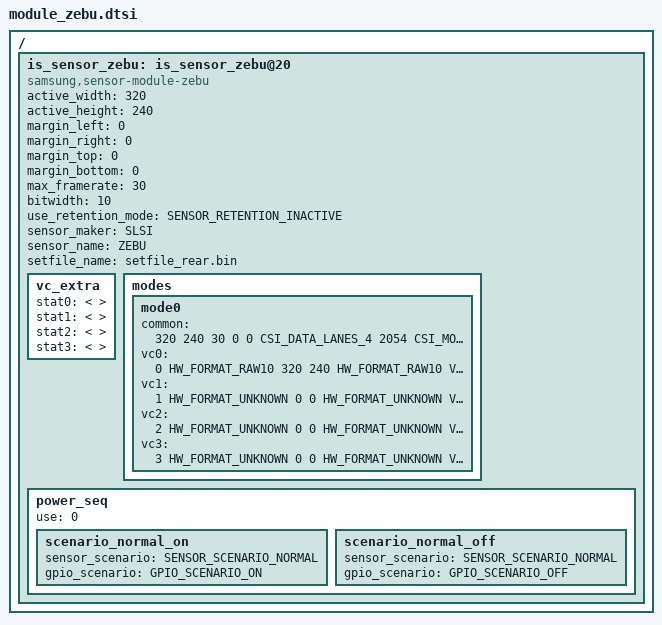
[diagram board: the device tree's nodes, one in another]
/*
 * GS101 board camera device tree source
 *
 * Copyright (c) 2019 Samsung Electronics Co., Ltd.
 *		http://www.samsung.com
 *
 * This program is free software; you can redistribute it and/or modify
 * it under the terms of the GNU General Public License version 2 as
 * published by the Free Software Foundation.
 */

#include <dt-bindings/camera/exynos_is_dt.h>

/ {
	fragment@camera {
		target-path = "/";
		__overlay__ {
			is_sensor_zebu: is_sensor_zebu@20 {
				compatible = "samsung,sensor-module-zebu";

				/* common */
				active_width = <320>;
				active_height = <240>;
				margin_left = <0>;
				margin_right = <0>;
				margin_top = <0>;
				margin_bottom = <0>;
				max_framerate = <30>;
				bitwidth = <10>;
				use_retention_mode = <SENSOR_RETENTION_INACTIVE>;
				sensor_maker = "SLSI";
				sensor_name = "ZEBU";
				setfile_name = "setfile_rear.bin";

				status = "okay";

				vc_extra {
					/* ex) statX = <stat_type, sensor_mode, max_width, max_height, max_element> */
					stat0 = </* not avaliable */>;	/* VC_BUF_DATA_TYPE_SENSOR_STAT1 */
					stat1 = </* not available */>;	/* VC_BUF_DATA_TYPE_GENERAL_STAT1 */
					stat2 = </* not avaliable */>;	/* VC_BUF_DATA_TYPE_SENSOR_STAT2 */
					stat3 = </* not available */>;	/* VC_BUF_DATA_TYPE_GENERAL_STAT2 */
				};

				/* sensor modes */
				modes {
						/* common = <width, height, fps, settle, mode, lane, speed, interleave, lrte, pd_mode> */
						/* vcX = <map, hwformat, width, height, hwformat, type, width, height> */
					mode0 {
						common = <320 240 30 0 0 CSI_DATA_LANES_4 2054 CSI_MODE_VC_ONLY LRTE_DISABLE PD_MOD1 EX_NONE>;
						vc0 = </* in */ 0 HW_FORMAT_RAW10 320 240	/* out */ HW_FORMAT_RAW10 VC_NOTHING 320 240>;
						vc1 = </* in */ 1 HW_FORMAT_UNKNOWN 0 0	/* out */ HW_FORMAT_UNKNOWN VC_NOTHING 0 0>;
						vc2 = </* in */ 2 HW_FORMAT_UNKNOWN 0 0		/* out */ HW_FORMAT_UNKNOWN VC_NOTHING 0 0>;
						vc3 = </* in */ 3 HW_FORMAT_UNKNOWN 0 0		/* out */ HW_FORMAT_UNKNOWN VC_NOTHING 0 0>;
					};
				};

				power_seq {
					use = <0>;
					scenario_normal_on {
						sensor_scenario = <SENSOR_SCENARIO_NORMAL>;
						gpio_scenario = <GPIO_SCENARIO_ON>;

						/* A start node number should be over the 10 for reserved number 0~9. */
						/* pname = "name"; pin = <act value dealy voltage>; gpio = <gpx# # 0x1>; */
					};

					scenario_normal_off {
						sensor_scenario = <SENSOR_SCENARIO_NORMAL>;
						gpio_scenario = <GPIO_SCENARIO_OFF>;

						/* A start node number should be over the 10 for reserved number 0~9. */
						/* pname = "name"; pin = <act value dealy voltage>; gpio = <gpx# # 0x1>; */
					};
				};
			};
		}; /* end of __overlay__ */
	}; /* end of fragment */
}; /* end of root */
